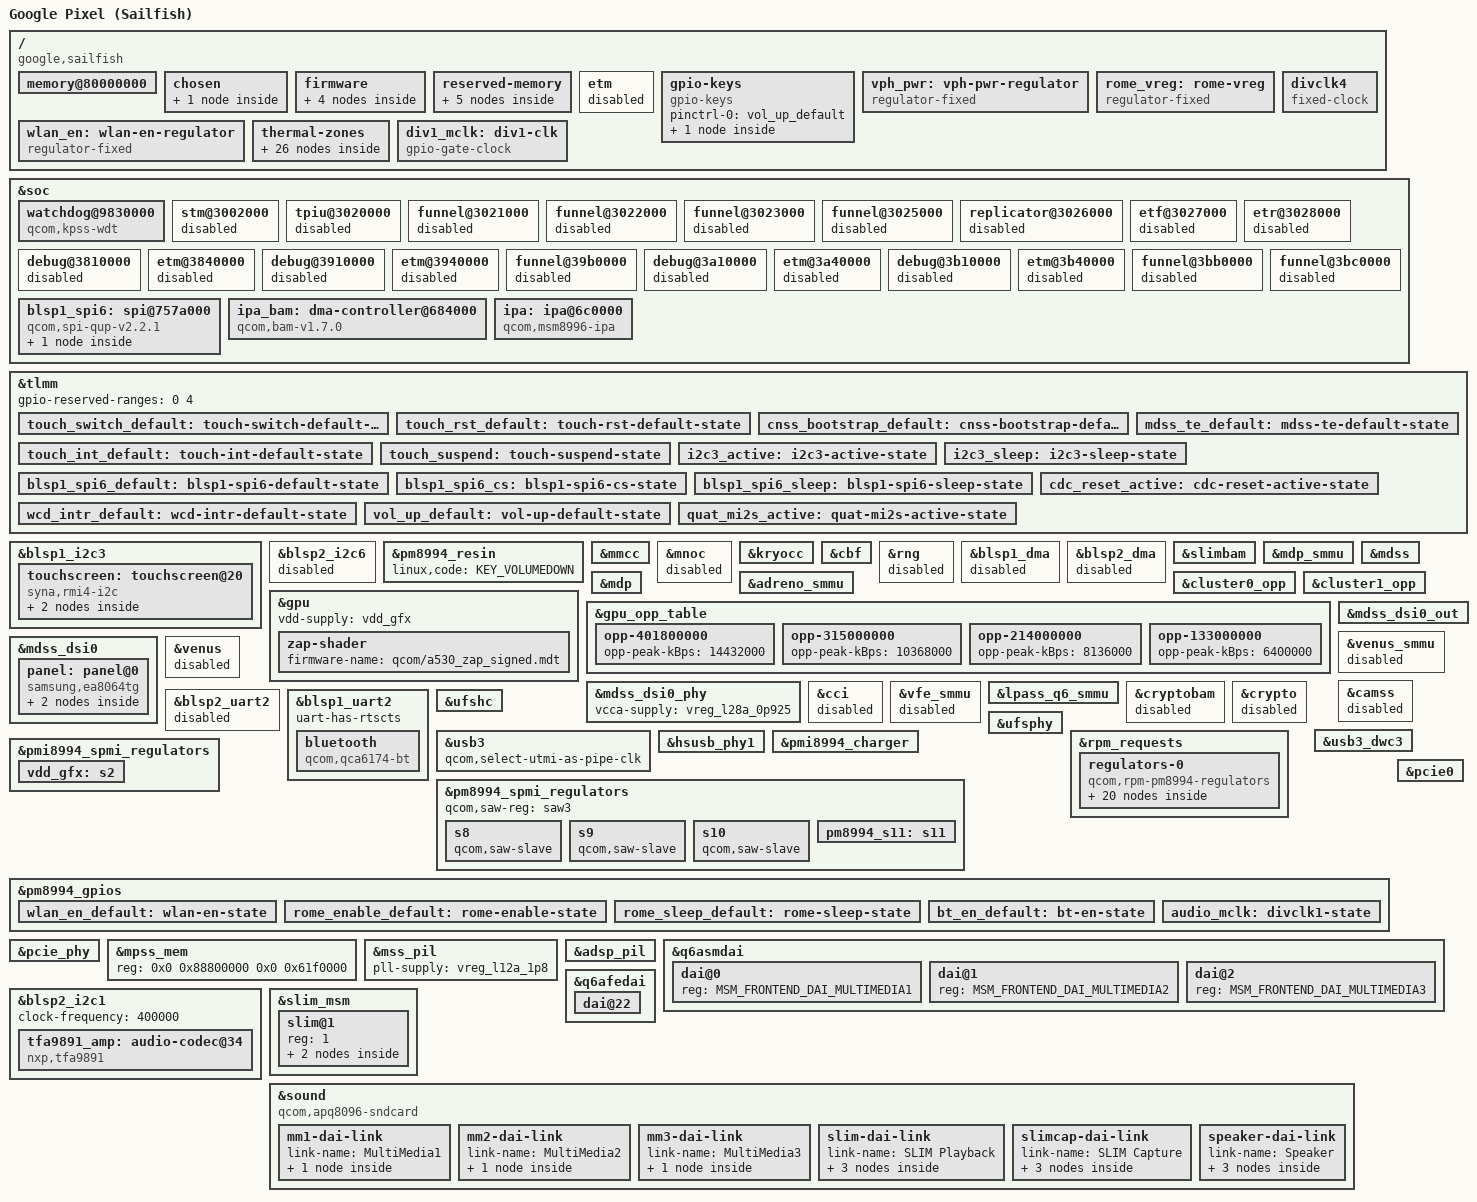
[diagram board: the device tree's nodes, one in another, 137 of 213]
// SPDX-License-Identifier: GPL-2.0-only
/*
 * Copyright (c) 2026, Linux Android Porting Team
 * Device Tree Source for Google Pixel (sailfish) - MSM8996 Pro
 */

/dts-v1/;

#include "msm8996pro.dtsi"
#include "pm8994.dtsi"
#include "pmi8994.dtsi"
#include "pmi8996.dtsi"
#include <dt-bindings/input/input.h>
#include <dt-bindings/gpio/gpio.h>
#include <dt-bindings/pinctrl/qcom,pmic-gpio.h>
#include <dt-bindings/sound/qcom,q6afe.h>
#include <dt-bindings/sound/qcom,q6asm.h>
#include <dt-bindings/sound/qcom,wcd9335.h>
#include <dt-bindings/thermal/thermal.h>

/ {
	model = "Google Pixel (Sailfish)";
	compatible = "google,sailfish", "qcom,msm8996pro", "qcom,msm8996";
	chassis-type = "handset";
	qcom,msm-id = <420 0x10001>, <421 0x10001>;
	qcom,board-id = <0x80 0>, <3 0>;
	qcom,pmic-id = <0x20009 0x10013 0x0 0x0>;

	/* 4GB LPDDR4 physical memory map */
	memory@80000000 {
		device_type = "memory";
		reg = <0x0 0x80000000 0x0 0x80000000>,
		      <0x1 0x00000000 0x0 0x7e550000>;
	};

	chosen {
		#address-cells = <2>;
		#size-cells = <2>;
		ranges;

		framebuffer0: framebuffer@c0000000 {
			compatible = "simple-framebuffer";
			reg = <0x0 0xc0000000 0x0 (1080 * 1920 * 3)>;
			width = <1080>;
			height = <1920>;
			stride = <(1080 * 3)>;
			format = "r8g8b8";
			memory-region = <&cont_splash_mem>;
		};
	};

	firmware {
		android {
			compatible = "android,firmware";
			fstab {
				compatible = "android,fstab";

				system {
					compatible = "android,system";
					dev = "/dev/block/platform/soc/624000.ufshc/by-name/system";
					type = "ext4";
					mnt_flags = "ro,barrier=1";
					fsmgr_flags = "wait,slotselect";
				};

				vendor {
					compatible = "android,vendor";
					dev = "/dev/block/platform/soc/624000.ufshc/by-name/vendor";
					type = "ext4";
					mnt_flags = "ro,barrier=1";
					fsmgr_flags = "wait,slotselect";
				};
			};
		};
	};

	reserved-memory {
		#address-cells = <2>;
		#size-cells = <2>;
		ranges;

		cont_splash_mem: memory@c0000000 {
			reg = <0x0 0xc0000000 0x0 0x3200000>;
			no-map;
		};

		dfps_data_mem: memory@83400000 {
			reg = <0x0 0x83400000 0x0 0x100000>;
			no-map;
		};

		ramoops@83500000 {
			compatible = "ramoops";
			reg = <0x0 0x83500000 0x0 0x100000>;
			record-size = <0x40000>;
			console-size = <0x80000>;
			pmsg-size = <0x40000>;
		};

		tz_bldr_mem: memory@83600000 {
			reg = <0x0 0x83600000 0x0 0xa00000>;
			no-map;
		};

		htc_radio_sec: memory@8e9f0000 {
			reg = <0x0 0x8e9f0000 0x0 0x10000>;
			no-map;
		};
	};

	etm {
		status = "disabled";
	};

	gpio-keys {
		compatible = "gpio-keys";
		pinctrl-names = "default";
		pinctrl-0 = <&vol_up_default>;

		key-vol-up {
			label = "Volume Up";
			gpios = <&tlmm 126 GPIO_ACTIVE_LOW>;
			linux,code = <KEY_VOLUMEUP>;
			wakeup-source;
			debounce-interval = <20>;
		};
	};

	vph_pwr: vph-pwr-regulator {
		compatible = "regulator-fixed";
		regulator-name = "vph_pwr";
		regulator-min-microvolt = <3600000>;
		regulator-max-microvolt = <3600000>;
		regulator-always-on;
		regulator-boot-on;
	};

	rome_vreg: rome-vreg {
		compatible = "regulator-fixed";
		regulator-name = "rome_vreg";
		regulator-min-microvolt = <3300000>;
		regulator-max-microvolt = <3300000>;
		startup-delay-us = <4000>;
		gpio = <&pm8994_gpios 9 GPIO_ACTIVE_HIGH>;
		enable-active-high;
		vin-supply = <&vph_pwr>;
		pinctrl-names = "default";
		pinctrl-0 = <&rome_enable_default>;
		regulator-always-on;
	};

	/*
	 * PM8994 GPIO18 DIV_CLK 32.768 kHz sleep clock for QCA6174. The pin is
	 * already muxed to FUNC2 by rome_sleep_default on &pcie0, so no pinctrl here.
	 */
	divclk4: divclk4 {
		compatible = "fixed-clock";
		#clock-cells = <0>;
		clock-frequency = <32768>;
		clock-output-names = "divclk4";
	};

	wlan_en: wlan-en-regulator {
		compatible = "regulator-fixed";
		regulator-name = "wlan_en";
		regulator-min-microvolt = <3300000>;
		regulator-max-microvolt = <3300000>;
		startup-delay-us = <70000>;
		gpio = <&pm8994_gpios 8 GPIO_ACTIVE_HIGH>;
		enable-active-high;
		vin-supply = <&rome_vreg>;
		pinctrl-names = "default";
		pinctrl-0 = <&wlan_en_default>;
	};
};

&soc {
	watchdog@9830000 {
		compatible = "qcom,kpss-wdt";
		reg = <0x09830000 0x1000>;
		clocks = <&sleep_clk>;
		timeout-sec = <30>;
	};

	/* Retail Sailfish TrustZone XPU-locks QDSS/CoreSight debug blocks */
	stm@3002000 { status = "disabled"; };
	tpiu@3020000 { status = "disabled"; };
	funnel@3021000 { status = "disabled"; };
	funnel@3022000 { status = "disabled"; };
	funnel@3023000 { status = "disabled"; };
	funnel@3025000 { status = "disabled"; };
	replicator@3026000 { status = "disabled"; };
	etf@3027000 { status = "disabled"; };
	etr@3028000 { status = "disabled"; };
	debug@3810000 { status = "disabled"; };
	etm@3840000 { status = "disabled"; };
	debug@3910000 { status = "disabled"; };
	etm@3940000 { status = "disabled"; };
	funnel@39b0000 { status = "disabled"; };
	debug@3a10000 { status = "disabled"; };
	etm@3a40000 { status = "disabled"; };
	debug@3b10000 { status = "disabled"; };
	etm@3b40000 { status = "disabled"; };
	funnel@3bb0000 { status = "disabled"; };
	funnel@3bc0000 { status = "disabled"; };

	/* STM32F411 Nanohub sensor hub on BLSP1 QUP6 SPI (gpio25-28) */
	blsp1_spi6: spi@757a000 {
		compatible = "qcom,spi-qup-v2.2.1";
		reg = <0x0757a000 0x600>;
		interrupts = <GIC_SPI 100 IRQ_TYPE_LEVEL_HIGH>;
		clocks = <&gcc GCC_BLSP1_QUP6_SPI_APPS_CLK>,
			 <&gcc GCC_BLSP1_AHB_CLK>;
		clock-names = "core", "iface";
		pinctrl-names = "default", "sleep";
		pinctrl-0 = <&blsp1_spi6_default &blsp1_spi6_cs>;
		pinctrl-1 = <&blsp1_spi6_sleep>;
		cs-gpios = <&tlmm 27 GPIO_ACTIVE_LOW>;
		spi-max-frequency = <19200000>;
		#address-cells = <1>;
		#size-cells = <0>;
		status = "okay";

		nanohub@0 {
			compatible = "google,nanohub";
			reg = <0>;
			spi-max-frequency = <19200000>;
			spi-cpol;
			spi-cpha;
		};
	};
};

&tlmm {
	/* gpio0..3 (blsp_spi1) are XPU-locked by TrustZone for the fingerprint sensor */
	gpio-reserved-ranges = <0 4>;

	touch_switch_default: touch-switch-default-state {
		pins = "gpio80";
		function = "gpio";
		drive-strength = <2>;
		bias-disable;
		output-low;
	};

	touch_rst_default: touch-rst-default-state {
		pins = "gpio89";
		function = "gpio";
		drive-strength = <2>;
		bias-disable;
		output-high;
	};

	cnss_bootstrap_default: cnss-bootstrap-default-state {
		pins = "gpio46";
		function = "gpio";
		drive-strength = <16>;
		bias-pull-down;
		output-low;
	};

	/*
	 * Command-mode panel tearing-effect line: route it to the MDP vsync
	 * input. The exact TE gpio is unconfirmed on Sailfish, so all three
	 * mdp_vsync-capable pins (10/11/12, unused here) are muxed as inputs.
	 */
	mdss_te_default: mdss-te-default-state {
		pins = "gpio10", "gpio11", "gpio12";
		function = "mdp_vsync";
		drive-strength = <2>;
		bias-pull-down;
	};

	touch_int_default: touch-int-default-state {
		pins = "gpio125";
		function = "gpio";
		drive-strength = <2>;
		bias-pull-up;
	};

	touch_suspend: touch-suspend-state {
		pins = "gpio89", "gpio125";
		function = "gpio";
		drive-strength = <2>;
		bias-disable;
	};

	i2c3_active: i2c3-active-state {
		pins = "gpio47", "gpio48";
		function = "blsp_i2c3";
		drive-strength = <8>;
		bias-pull-up;
	};

	i2c3_sleep: i2c3-sleep-state {
		pins = "gpio47", "gpio48";
		function = "blsp_i2c3";
		drive-strength = <8>;
		bias-pull-up;
	};

	blsp1_spi6_default: blsp1-spi6-default-state {
		pins = "gpio25", "gpio26", "gpio28";
		function = "blsp_spi6";
		drive-strength = <12>;
		bias-disable;
	};

	blsp1_spi6_cs: blsp1-spi6-cs-state {
		pins = "gpio27";
		function = "gpio";
		drive-strength = <12>;
		bias-disable;
		output-high;
	};

	blsp1_spi6_sleep: blsp1-spi6-sleep-state {
		pins = "gpio25", "gpio26", "gpio27", "gpio28";
		function = "gpio";
		drive-strength = <2>;
		bias-pull-down;
	};
};

&blsp1_i2c3 {
	/delete-property/ dmas;
	/delete-property/ dma-names;
	clock-frequency = <400000>;
	assigned-clocks = <&gcc GCC_BLSP1_QUP3_I2C_APPS_CLK>;
	assigned-clock-rates = <19200000>;
	pinctrl-names = "default", "sleep";
	pinctrl-0 = <&i2c3_active>;
	pinctrl-1 = <&i2c3_sleep>;
	status = "okay";

	touchscreen: touchscreen@20 {
		compatible = "syna,rmi4-i2c";
		reg = <0x20>;
		#address-cells = <1>;
		#size-cells = <0>;
		interrupts-extended = <&tlmm 125 IRQ_TYPE_LEVEL_LOW>;
		reset-gpios = <&tlmm 89 GPIO_ACTIVE_LOW>;
		switch-gpios = <&tlmm 80 GPIO_ACTIVE_HIGH>;
		vdd-supply = <&vreg_l29a_3p0>;
		vio-supply = <&vreg_lvs2a_1p8>;

		pinctrl-names = "default", "sleep";
		pinctrl-0 = <&touch_rst_default &touch_int_default &touch_switch_default>;
		pinctrl-1 = <&touch_suspend>;

		syna,startup-delay-ms = <100>;

		rmi4-f01@1 {
			reg = <0x01>;
			syna,nosleep-mode = <2>;
		};

		rmi4-f12@12 {
			reg = <0x12>;
			touchscreen-x-mm = <62>;
			touchscreen-y-mm = <111>;
			syna,sensor-type = <1>;
		};
	};
};

&blsp2_i2c6 {
	status = "disabled";
};

&pm8994_resin {
	linux,code = <KEY_VOLUMEDOWN>;
	status = "okay";
};

/*
 * Keep native display/MMSS clocks, unused SMMUs, TZ-owned crypto/PRNG,
 * and unused BAM DMA controllers disabled during early bring-up so
 * continuous splash stays intact and TZ XPU regions are untouched.
 */
&mmcc {
	clocks = <&xo_board>,
		 <&gcc GPLL0>,
		 <&gcc GCC_MMSS_NOC_CFG_AHB_CLK>;
	clock-names = "xo",
		      "gpll0",
		      "gcc_mmss_noc_cfg_ahb_clk";
	protected-clocks = <MMSS_MMAGIC_AHB_CLK>,
			   <MMSS_MMAGIC_CFG_AHB_CLK>,
			   <MMSS_MMAGIC_AXI_CLK>,
			   <MMSS_MMAGIC_MAXI_CLK>,
			   <MMAGIC_BIMC_AXI_CLK>,
			   <MMAGIC_BIMC_NOC_CFG_AHB_CLK>,
			   <MMAGIC_CAMSS_AXI_CLK>,
			   <MMAGIC_CAMSS_NOC_CFG_AHB_CLK>,
			   <MMAGIC_VIDEO_AXI_CLK>,
			   <MMAGIC_VIDEO_NOC_CFG_AHB_CLK>;
	/delete-property/ assigned-clocks;
	/delete-property/ assigned-clock-rates;
	status = "okay";
};

&mnoc {
	status = "disabled";
};

/* Enable Kryo CPU and CBF clocks alongside PM8994 S11 SAW regulator and CPU cooling maps */
&kryocc {
	status = "okay";
};

&cbf {
	status = "okay";
};

&rng {
	status = "disabled";
};

&blsp1_dma {
	status = "disabled";
};

&blsp2_dma {
	status = "disabled";
};

&slimbam {
	status = "okay";
};

&mdp_smmu {
	/delete-property/ power-domains;
	qcom,skip-init;
	qcom,no-smr-check;
	status = "okay";
};

&mdss {
	/delete-property/ power-domains;
	status = "okay";
};

&mdp {
	/delete-property/ assigned-clocks;
	/delete-property/ assigned-clock-rates;
	/delete-property/ interconnects;
	/delete-property/ interconnect-names;
	status = "okay";
};

&adreno_smmu {
	/delete-property/ power-domains;
	status = "okay";
};

&gpu {
	/delete-property/ power-domains;
	vdd-supply = <&vdd_gfx>;
	status = "okay";

	zap-shader {
		firmware-name = "qcom/a530_zap_signed.mdt";
	};
};

/*
 * Keep CPU clocks within Pixel Sailfish's nominal CPR operating window
 * (0.96V-1.015V, <= 1.59 GHz cluster0 / <= 1.90 GHz cluster1) since dynamic
 * CPRh rail scaling is not active on mainline MSM8996.
 */
&cluster0_opp {
	/delete-node/ opp-1996800000;
	/delete-node/ opp-2188800000;
};

&cluster1_opp {
	/delete-node/ opp-1977600000;
	/delete-node/ opp-2054400000;
	/delete-node/ opp-2150400000;
	/delete-node/ opp-2246400000;
	/delete-node/ opp-2342400000;
};

/*
 * Keep GPU clock within the fixed bootloader nominal vdd_gfx voltage corner
 * (<= 401.8 MHz) since dynamic CPR3/APM rail scaling is not active.
 */
&gpu_opp_table {
	/delete-node/ opp-652800000;
	/delete-node/ opp-624000000;
	/delete-node/ opp-560000000;
	/delete-node/ opp-510000000;

	opp-401800000 {
		opp-peak-kBps = <14432000>;
	};
	opp-315000000 {
		opp-peak-kBps = <10368000>;
	};
	opp-214000000 {
		opp-peak-kBps = <8136000>;
	};
	opp-133000000 {
		opp-peak-kBps = <6400000>;
	};
};

&mdss_dsi0 {
	/delete-property/ assigned-clocks;
	/delete-property/ assigned-clock-parents;
	vdda-supply = <&vreg_l2a_1p25>;
	vcca-supply = <&vreg_l28a_0p925>;
	pinctrl-names = "default";
	pinctrl-0 = <&mdss_te_default>;
	status = "okay";

	panel: panel@0 {
		compatible = "samsung,ea8064tg";
		reg = <0>;

		vddio-supply = <&vreg_lvs2a_1p8>;
		vci-supply = <&vreg_l29a_3p0>;
		reset-gpios = <&tlmm 39 GPIO_ACTIVE_LOW>;

		port {
			panel_in: endpoint {
				remote-endpoint = <&mdss_dsi0_out>;
			};
		};
	};
};

&mdss_dsi0_out {
	remote-endpoint = <&panel_in>;
	data-lanes = <0 1 2 3>;
};

&mdss_dsi0_phy {
	vcca-supply = <&vreg_l28a_0p925>;
	status = "okay";
};

&venus_smmu {
	status = "disabled";
};

&venus {
	status = "disabled";
};

&camss {
	status = "disabled";
};

&cci {
	status = "disabled";
};

&vfe_smmu {
	status = "disabled";
};

&lpass_q6_smmu {
	status = "okay";
};

&cryptobam {
	status = "disabled";
};

&crypto {
	status = "disabled";
};

&blsp2_uart2 {
	status = "disabled";
};

/* QCA6174 (Rome 3.2) Bluetooth HCI over BLSP1 UART2 (gpio41-44) */
&blsp1_uart2 {
	uart-has-rtscts;
	status = "okay";

	bluetooth {
		compatible = "qcom,qca6174-bt";
		pinctrl-names = "default";
		pinctrl-0 = <&bt_en_default>;
		enable-gpios = <&pm8994_gpios 19 GPIO_ACTIVE_HIGH>;
		clocks = <&divclk4>;
		firmware-name = "btnv32.bin", "btfw32.tlv";
	};
};

&ufshc {
	vcc-supply = <&vreg_l20a_2p95>;
	vccq-supply = <&vreg_l25a_1p2>;
	vccq2-supply = <&vreg_s4a_1p8>;
	vdd-hba-supply = <&vreg_l25a_1p2>;

	vcc-max-microamp = <600000>;
	vccq-max-microamp = <450000>;
	vccq2-max-microamp = <450000>;

	status = "okay";
};

&ufsphy {
	status = "okay";
	vdda-phy-supply = <&vreg_l28a_0p925>;
	vdda-pll-supply = <&vreg_l12a_1p8>;
};

&usb3 {
	status = "okay";
	qcom,select-utmi-as-pipe-clk;
};

&usb3_dwc3 {
	dr_mode = "peripheral";
	maximum-speed = "high-speed";
	phys = <&hsusb_phy1>;
	phy-names = "usb2-phy";
	snps,is-utmi-l1-suspend;
	snps,usb2-gadget-lpm-disable;
};

&hsusb_phy1 {
	status = "okay";
	vdd-supply = <&vreg_l28a_0p925>;
	vdda-pll-supply = <&vreg_l12a_1p8>;
	vdda-phy-dpdm-supply = <&vreg_l24a_3p075>;
};

&rpm_requests {
	regulators-0 {
		compatible = "qcom,rpm-pm8994-regulators";

		vreg_s3a_1p3: s3 {
			regulator-name = "vreg_s3a_1p3";
			regulator-min-microvolt = <1300000>;
			regulator-max-microvolt = <1300000>;
			regulator-always-on;
		};

		vreg_s4a_1p8: s4 {
			regulator-min-microvolt = <1800000>;
			regulator-max-microvolt = <1800000>;
			regulator-always-on;
		};

		vreg_l2a_1p25: l2 {
			regulator-min-microvolt = <1250000>;
			regulator-max-microvolt = <1250000>;
		};

		vreg_l6a_1p8: l6 {
			regulator-min-microvolt = <1800000>;
			regulator-max-microvolt = <1800000>;
			regulator-always-on;
		};

		vreg_l12a_1p8: l12 {
			regulator-min-microvolt = <1800000>;
			regulator-max-microvolt = <1800000>;
		};

		vreg_l14a_1p8: l14 {
			regulator-min-microvolt = <1800000>;
			regulator-max-microvolt = <1800000>;
			regulator-always-on;
		};

		vreg_l17a_3p3: l17 {
			regulator-min-microvolt = <3300000>;
			regulator-max-microvolt = <3300000>;
			regulator-always-on;
		};

		vreg_l18a_1p8: l18 {
			regulator-min-microvolt = <1800000>;
			regulator-max-microvolt = <1800000>;
			regulator-always-on;
		};

		vreg_l19a_2p85: l19 {
			regulator-min-microvolt = <2850000>;
			regulator-max-microvolt = <2850000>;
			regulator-always-on;
		};

		vreg_l20a_2p95: l20 {
			regulator-min-microvolt = <2950000>;
			regulator-max-microvolt = <2950000>;
			regulator-allow-set-load;
		};

		vreg_l21a_3p0: l21 {
			regulator-min-microvolt = <3000000>;
			regulator-max-microvolt = <3000000>;
			regulator-always-on;
		};

		vreg_l22a_3p0: l22 {
			regulator-min-microvolt = <3000000>;
			regulator-max-microvolt = <3300000>;
			regulator-always-on;
		};

		vreg_l23a_2p8: l23 {
			regulator-min-microvolt = <2800000>;
			regulator-max-microvolt = <2800000>;
			regulator-always-on;
		};

		vreg_l24a_3p075: l24 {
			regulator-min-microvolt = <3075000>;
			regulator-max-microvolt = <3075000>;
		};

		vreg_l25a_1p2: l25 {
			regulator-min-microvolt = <1200000>;
			regulator-max-microvolt = <1200000>;
			regulator-allow-set-load;
		};

		vreg_l28a_0p925: l28 {
			regulator-min-microvolt = <925000>;
			regulator-max-microvolt = <925000>;
			regulator-allow-set-load;
		};

		vreg_l29a_3p0: l29 {
			regulator-min-microvolt = <3000000>;
			regulator-max-microvolt = <3000000>;
			regulator-always-on;
		};

		vreg_l30a_1p8: l30 {
			regulator-min-microvolt = <1800000>;
			regulator-max-microvolt = <1800000>;
			regulator-always-on;
		};

		vreg_lvs1a_1p8: lvs1 {
			regulator-always-on;
		};

		vreg_lvs2a_1p8: lvs2 {
			regulator-always-on;
		};
	};
};

&pmi8994_charger {
	qcom,fast-charge-current-limit = <1500000>;
	qcom,fast-charge-safe-current = <1500000>;
	qcom,fast-charge-high-threshold-voltage = <4350000>;
	qcom,fast-charge-safe-voltage = <4350000>;
	usb-charge-current-limit = <1500000>;
	qcom,disable-dc;
	status = "okay";
};

&pm8994_spmi_regulators {
	qcom,saw-reg = <&saw3>;

	s8 {
		qcom,saw-slave;
	};

	s9 {
		qcom,saw-slave;
	};

	s10 {
		qcom,saw-slave;
	};

	pm8994_s11: s11 {
		qcom,saw-leader;
		regulator-name = "pm8994_s11";
		regulator-min-microvolt = <960000>;
		regulator-max-microvolt = <1015000>;
		regulator-max-step-microvolt = <150000>;
		regulator-always-on;
	};
};

&pmi8994_spmi_regulators {
	vdd_gfx: s2 {
		regulator-name = "vdd_gfx";
		regulator-min-microvolt = <300000>;
		regulator-max-microvolt = <1065000>;
		regulator-enable-ramp-delay = <1600>;
		regulator-always-on;
		regulator-boot-on;
	};
};

&mmcc {
	vdd-gfx-supply = <&vdd_gfx>;
};

/ {
	thermal-zones {
		cpu0-thermal {
			polling-delay = <1000>;
			polling-delay-passive = <1000>;

			trips {
				cpu0_alert0: trip-point0 {
					temperature = <82000>;
				};
			};

			cooling-maps {
				map0 {
					trip = <&cpu0_alert0>;
					cooling-device = <&cpu0 THERMAL_NO_LIMIT THERMAL_NO_LIMIT>;
				};
			};
		};

		cpu1-thermal {
			polling-delay = <1000>;
			polling-delay-passive = <1000>;

			trips {
				cpu1_alert0: trip-point0 {
					temperature = <82000>;
				};
			};

			cooling-maps {
				map0 {
					trip = <&cpu1_alert0>;
					cooling-device = <&cpu0 THERMAL_NO_LIMIT THERMAL_NO_LIMIT>;
				};
			};
		};

		cpu2-thermal {
			polling-delay = <1000>;
			polling-delay-passive = <1000>;

			trips {
				cpu2_alert0: trip-point0 {
					temperature = <82000>;
				};
			};

			cooling-maps {
				map0 {
					trip = <&cpu2_alert0>;
					cooling-device = <&cpu2 THERMAL_NO_LIMIT THERMAL_NO_LIMIT>;
				};
			};
		};

		cpu3-thermal {
			polling-delay = <1000>;
			polling-delay-passive = <1000>;

			trips {
				cpu3_alert0: trip-point0 {
					temperature = <82000>;
				};
			};

			cooling-maps {
				map0 {
					trip = <&cpu3_alert0>;
					cooling-device = <&cpu2 THERMAL_NO_LIMIT THERMAL_NO_LIMIT>;
				};
			};
		};

		gpu-top-thermal {
			polling-delay = <1000>;
			polling-delay-passive = <500>;

			trips {
				gpu1_alert0: trip-point0 {
					temperature = <88000>;
				};
			};
		};

		gpu-bottom-thermal {
			polling-delay = <1000>;
			polling-delay-passive = <500>;

			trips {
				gpu2_alert0: trip-point0 {
					temperature = <88000>;
				};
			};
		};
	};
};

&pm8994_gpios {
	wlan_en_default: wlan-en-state {
		pins = "gpio8";
		function = PMIC_GPIO_FUNC_NORMAL;
		output-low;
		drive-push-pull;
		bias-disable;
		qcom,drive-strength = <PMIC_GPIO_STRENGTH_LOW>;
		power-source = <PM8994_GPIO_S4>;
	};

	rome_enable_default: rome-enable-state {
		pins = "gpio9";
		function = PMIC_GPIO_FUNC_NORMAL;
		output-high;
		drive-push-pull;
		bias-disable;
		qcom,drive-strength = <PMIC_GPIO_STRENGTH_LOW>;
		power-source = <PM8994_GPIO_VPH>;
	};

	rome_sleep_default: rome-sleep-state {
		pins = "gpio18";
		function = PMIC_GPIO_FUNC_FUNC2;
		output-low;
		drive-push-pull;
		bias-disable;
		qcom,drive-strength = <PMIC_GPIO_STRENGTH_MED>;
		power-source = <PM8994_GPIO_S4>;
	};

	bt_en_default: bt-en-state {
		pins = "gpio19";
		function = PMIC_GPIO_FUNC_NORMAL;
		output-low;
		drive-push-pull;
		bias-pull-down;
		qcom,drive-strength = <PMIC_GPIO_STRENGTH_LOW>;
		power-source = <PM8994_GPIO_S4>;
	};

	audio_mclk: divclk1-state {
		pins = "gpio15";
		function = PMIC_GPIO_FUNC_FUNC1;
		power-source = <PM8994_GPIO_S4>;
	};
};

&pcie_phy {
	vdda-phy-supply = <&vreg_l28a_0p925>;
	vdda-pll-supply = <&vreg_l12a_1p8>;
	status = "okay";
};

&pcie0 {
	perst-gpios = <&tlmm 35 GPIO_ACTIVE_LOW>;
	wake-gpios = <&tlmm 37 GPIO_ACTIVE_HIGH>;
	vdda-supply = <&vreg_l28a_0p925>;
	vddpe-3v3-supply = <&wlan_en>;
	pinctrl-0 = <&pcie0_state_on &cnss_bootstrap_default &rome_sleep_default>;
	status = "okay";
};

&mpss_mem {
	reg = <0x0 0x88800000 0x0 0x61f0000>;
};

&mss_pil {
	pll-supply = <&vreg_l12a_1p8>;
	status = "okay";
};

&soc {
	ipa_bam: dma-controller@684000 {
		compatible = "qcom,bam-v1.7.0";
		reg = <0x00684000 0x26934>;
		interrupts = <GIC_SPI 432 IRQ_TYPE_LEVEL_HIGH>;
		clocks = <&rpmcc RPM_SMD_IPA_CLK>;
		clock-names = "bam_clk";
		qcom,controlled-remotely;
		#dma-cells = <1>;
		qcom,ee = <0>;
	};

	ipa: ipa@6c0000 {
		compatible = "qcom,msm8996-ipa";
		reg = <0x006c0000 0x5000>,
		      <0x006c5000 0x4000>;
		reg-names = "ipa-reg", "ipa-shared";
		interrupts = <GIC_SPI 333 IRQ_TYPE_EDGE_RISING>;
		interrupt-names = "ipa";
		clocks = <&rpmcc RPM_SMD_IPA_CLK>;
		clock-names = "core";
		interconnects = <&a2noc MASTER_IPA &bimc SLAVE_EBI_CH0>,
				<&a2noc MASTER_IPA &snoc SLAVE_IMEM>;
		interconnect-names = "memory", "imem";
		dmas = <&ipa_bam 2>, <&ipa_bam 3>, <&ipa_bam 4>, <&ipa_bam 5>;
		dma-names = "ap_lan_rx", "cmd_tx", "ap_modem_tx", "ap_modem_rx";
	};
};

/ {
	div1_mclk: div1-clk {
		compatible = "gpio-gate-clock";
		pinctrl-names = "default";
		pinctrl-0 = <&audio_mclk>;
		#clock-cells = <0>;
		clocks = <&rpmcc RPM_SMD_DIV_CLK1>;
		enable-gpios = <&pm8994_gpios 15 GPIO_ACTIVE_HIGH>;
	};
};

&adsp_pil {
	status = "okay";
};

&q6asmdai {
	#address-cells = <1>;
	#size-cells = <0>;

	dai@0 {
		reg = <MSM_FRONTEND_DAI_MULTIMEDIA1>;
	};

	dai@1 {
		reg = <MSM_FRONTEND_DAI_MULTIMEDIA2>;
	};

	dai@2 {
		reg = <MSM_FRONTEND_DAI_MULTIMEDIA3>;
	};
};

&blsp2_i2c1 {
	/delete-property/ dmas;
	/delete-property/ dma-names;
	clock-frequency = <400000>;
	status = "okay";

	tfa9891_amp: audio-codec@34 {
		compatible = "nxp,tfa9891";
		reg = <0x34>;
		vddd-supply = <&vreg_s4a_1p8>;
		reset-gpios = <&pm8994_gpios 5 GPIO_ACTIVE_HIGH>;
		#sound-dai-cells = <0>;
	};
};

&q6afedai {
	dai@22 {
		reg = <QUATERNARY_MI2S_RX>;
		qcom,sd-lines = <1>;
	};
};

&slim_msm {
	status = "okay";

	slim@1 {
		reg = <1>;
		#address-cells = <2>;
		#size-cells = <0>;

		tasha_ifd: tas-ifd@0,0 {
			compatible = "slim217,1a0";
			reg = <0 0>;
		};

		wcd9335: codec@1,0 {
			compatible = "slim217,1a0";
			reg = <1 0>;

			clock-names = "mclk", "slimbus";
			clocks = <&div1_mclk>,
				 <&rpmcc RPM_SMD_BB_CLK1>;
			interrupt-parent = <&tlmm>;
			interrupts = <54 IRQ_TYPE_LEVEL_HIGH>,
				     <53 IRQ_TYPE_LEVEL_HIGH>;
			interrupt-names = "intr1", "intr2";
			interrupt-controller;
			#interrupt-cells = <1>;

			pinctrl-0 = <&cdc_reset_active &wcd_intr_default>;
			pinctrl-names = "default";

			reset-gpios = <&tlmm 64 GPIO_ACTIVE_LOW>;
			slim-ifc-dev = <&tasha_ifd>;

			#sound-dai-cells = <1>;

			vdd-buck-supply = <&vreg_s4a_1p8>;
			vdd-buck-sido-supply = <&vreg_s4a_1p8>;
			vdd-tx-supply = <&vreg_s4a_1p8>;
			vdd-rx-supply = <&vreg_s4a_1p8>;
			vdd-io-supply = <&vreg_s4a_1p8>;
		};
	};
};

&sound {
	compatible = "qcom,apq8096-sndcard";
	model = "Pixel Sailfish";
	pinctrl-names = "default";
	pinctrl-0 = <&quat_mi2s_active>;
	audio-routing = "RX_BIAS", "MCLK";

	mm1-dai-link {
		link-name = "MultiMedia1";
		cpu {
			sound-dai = <&q6asmdai MSM_FRONTEND_DAI_MULTIMEDIA1>;
		};
	};

	mm2-dai-link {
		link-name = "MultiMedia2";
		cpu {
			sound-dai = <&q6asmdai MSM_FRONTEND_DAI_MULTIMEDIA2>;
		};
	};

	mm3-dai-link {
		link-name = "MultiMedia3";
		cpu {
			sound-dai = <&q6asmdai MSM_FRONTEND_DAI_MULTIMEDIA3>;
		};
	};

	slim-dai-link {
		link-name = "SLIM Playback";
		cpu {
			sound-dai = <&q6afedai SLIMBUS_6_RX>;
		};
		platform {
			sound-dai = <&q6routing>;
		};
		codec {
			sound-dai = <&wcd9335 AIF4_PB>;
		};
	};

	slimcap-dai-link {
		link-name = "SLIM Capture";
		cpu {
			sound-dai = <&q6afedai SLIMBUS_0_TX>;
		};
		platform {
			sound-dai = <&q6routing>;
		};
		codec {
			sound-dai = <&wcd9335 AIF1_CAP>;
		};
	};

	speaker-dai-link {
		link-name = "Speaker";
		cpu {
			sound-dai = <&q6afedai QUATERNARY_MI2S_RX>;
		};
		platform {
			sound-dai = <&q6routing>;
		};
		codec {
			sound-dai = <&tfa9891_amp>;
		};
	};
};

&tlmm {
	cdc_reset_active: cdc-reset-active-state {
		pins = "gpio64";
		function = "gpio";
		drive-strength = <16>;
		bias-disable;
		output-high;
	};

	wcd_intr_default: wcd-intr-default-state {
		pins = "gpio53", "gpio54";
		function = "gpio";
		drive-strength = <2>;
		bias-pull-down;
		input-enable;
	};

	vol_up_default: vol-up-default-state {
		pins = "gpio126";
		function = "gpio";
		drive-strength = <2>;
		bias-pull-up;
		input-enable;
	};

	quat_mi2s_active: quat-mi2s-active-state {
		pins = "gpio58", "gpio59", "gpio60", "gpio61";
		function = "qua_mi2s";
		drive-strength = <8>;
		bias-disable;
	};
};

